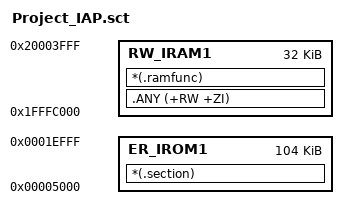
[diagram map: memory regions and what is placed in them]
; *************************************************************
; *** Scatter-Loading Description File generated by uVision ***
; *************************************************************

LR_IROM1 0x00005000 0x0001A000  {    ; load region size_region
  ER_IROM1 0x00005000 0x0001A000  {  ; load address = execution address
   *.o (RESET, +First)
   *(InRoot$$Sections)
   .ANY (+RO)
   .ANY (+XO)
  }
  SECTION + 0
  {
    *(.section)
  }
  RW_IRAM1 0x1FFFC000 0x00008000  {  ; RW data
   .ANY (+RW +ZI)
   *(.ramfunc)
  }
}

